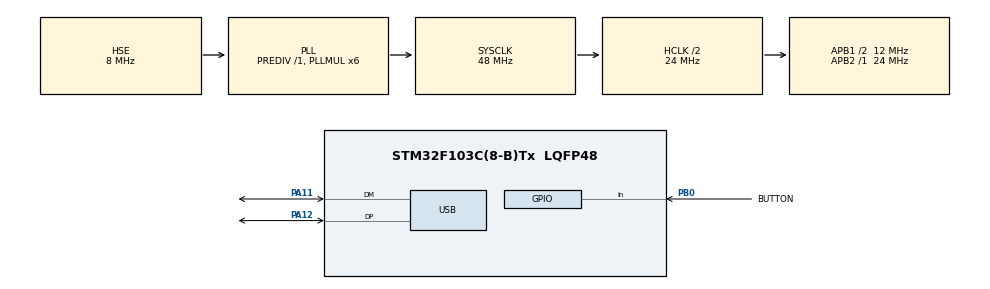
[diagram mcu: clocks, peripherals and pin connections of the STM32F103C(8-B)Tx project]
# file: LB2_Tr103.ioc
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Mcu.Family=STM32F1
Mcu.Name=STM32F103C(8-B)Tx
Mcu.Package=LQFP48
NVIC.PriorityGroup=NVIC_PRIORITYGROUP_4
NVIC.TIM2_IRQn=true\:0\:0\:false\:false\:true\:true\:true\:true
NVIC.TIM4_IRQn=true\:0\:0\:false\:false\:true\:true\:true\:true
NVIC.USB_LP_CAN1_RX0_IRQn=true\:0\:0\:false\:false\:true\:false\:true\:true
PA11.Mode=Device
PA11.Signal=USB_DM
PA12.Mode=Device
PA12.Signal=USB_DP
PA13.Mode=Serial_Wire
PA13.Signal=SYS_JTMS-SWDIO
PA14.Mode=Serial_Wire
PA14.Signal=SYS_JTCK-SWCLK
PB0.GPIO_Label=BUTTON
PB0.Signal=GPIO_Input
PD0-OSC_IN.Mode=HSE-External-Oscillator
PD0-OSC_IN.Signal=RCC_OSC_IN
PD1-OSC_OUT.Mode=HSE-External-Oscillator
PD1-OSC_OUT.Signal=RCC_OSC_OUT
ProjectManager.HeapSize=0x200
ProjectManager.StackSize=0x400
ProjectManager.TargetToolchain=STM32CubeIDE
RCC.AHBCLKDivider=RCC_SYSCLK_DIV2
RCC.AHBFreq_Value=24000000
RCC.APB1CLKDivider=RCC_HCLK_DIV2
RCC.APB1Freq_Value=12000000
RCC.APB1TimFreq_Value=24000000
RCC.APB2Freq_Value=24000000
RCC.APB2TimFreq_Value=24000000
RCC.HCLKFreq_Value=24000000
RCC.PLLMUL=RCC_PLL_MUL6
RCC.SYSCLKFreq_VALUE=48000000
RCC.SYSCLKSource=RCC_SYSCLKSOURCE_PLLCLK
RCC.USBFreq_Value=48000000
TIM2.Channel-PWM\ Generation1\ No\ Output=TIM_CHANNEL_1
TIM2.Period=7500
TIM2.Prescaler=32
TIM4.Channel-PWM\ Generation1\ No\ Output=TIM_CHANNEL_1
TIM4.Period=7500
TIM4.Prescaler=32
USB_DEVICE.APP_RX_DATA_SIZE=1024
USB_DEVICE.APP_TX_DATA_SIZE=1024
USB_DEVICE.CLASS_NAME_FS=CDC
USB_DEVICE.VirtualMode=Cdc
USB_DEVICE.VirtualModeFS=Cdc_FS
VP_TIM2_VS_no_output1.Mode=PWM Generation1 No Output
VP_TIM4_VS_no_output1.Mode=PWM Generation1 No Output
VP_USB_DEVICE_VS_USB_DEVICE_CDC_FS.Mode=CDC_FS
board=custom

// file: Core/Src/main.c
/* USER CODE BEGIN Header */
/**
  ******************************************************************************
  * @file           : main.c
  * @brief          : Main program body
  ******************************************************************************
  * @attention
  *
  * Copyright (c) 2023 STMicroelectronics.
  * All rights reserved.
  *
  * This software is licensed under terms that can be found in the LICENSE file
  * in the root directory of this software component.
  * If no LICENSE file comes with this software, it is provided AS-IS.
  *
  ******************************************************************************
  */
/* USER CODE END Header */
#include "main.h"
#include "tim.h"
#include "usb_device.h"
#include "gpio.h"

/* USER CODE BEGIN Includes */
#include "usbd_cdc_if.h"
#include "math.h"

/* USER CODE END Includes */

/* USER CODE BEGIN PV */
uint8_t lenn;
int16_t k = 1;
int8_t status = 0;
int8_t r = 10;
int8_t poz = 0;
float T2 = 0.196;
float T1 = 0.077;
float t = 0;
float tp = 0;
float f1,f2,f3,f4,f5, F = 0, Fv = 0;
uint8_t Fit = 0, sizeL;
int8_t state = 0;
char str[2];

/* USER CODE END PV */

void SystemClock_Config(void);

int main(void)
{

  /* MCU Configuration--------------------------------------------------------*/

  /* Reset of all peripherals, Initializes the Flash interface and the Systick. */
  HAL_Init();

  /* Configure the system clock */
  SystemClock_Config();

  /* Initialize all configured peripherals */
  MX_GPIO_Init();
  MX_USB_DEVICE_Init();
  MX_TIM2_Init();
  MX_TIM4_Init();
  /* USER CODE BEGIN 2 */
  HAL_TIM_Base_Start_IT(&htim2);
  HAL_TIM_Base_Start_IT(&htim4);
  /* USER CODE END 2 */

  /* Infinite loop */
  /* USER CODE BEGIN WHILE */
  while (1)
  {
	  status = HAL_GPIO_ReadPin(BUTTON_GPIO_Port, BUTTON_Pin);
	  if (status == 1 && poz != 1) {
		  r = rand() % 4;
		  tp = 0;
		  poz = 1;
	  }
	  else if (status == 0 && poz == 1) {
		  poz = 10;
	  }

	  if (r == 0) {
	  	Fv = 0.1 * (1.0206 * exp(-0.2 * tp) * sin(0.9798 * tp));
	  }
	  else if (r == 1) {
	  	Fv = 0.3 * (1.0206 * exp(-0.2 * tp) * sin(0.9798 * tp));
	  }
	  else if (r == 2) {
	  	Fv = 0.55 * (1.0206 * exp(-0.2 * tp) * sin(0.9798 * tp));
	  }
	  else if (r == 3) {
	  	Fv = 0.7 * (1.0206 * exp(-0.2 * tp) * sin(0.9798 * tp));
	  }

	  f1 = sqrt((4*pow(T2,2) - pow(T1,2))/(4*pow(T2,4)));
	  f2 = -T1 * k * exp(-T1*t/(2*pow(T2,2)))*sin(t * f1);
	  f3 = 2 * pow(T2,2) * k * f1;
	  f4 = - 2 * pow(T2,2) * k * f1 * exp(-T1*t/(2*pow(T2,2))) * cos(t * f1);
	  f5 = 2 * pow(T2,2) * f1;
	  F = (f2 + f3 + f4) / f5 + Fv;
	  Fit = (uint8_t) round(F * 10);

	  sizeL = sprintf(str, "%u\n", Fit);

	  CDC_Transmit_FS((uint8_t*) str, sizeL);

	  HAL_Delay(10);

    /* USER CODE END WHILE */

  }
}

void SystemClock_Config(void)
{
  RCC_OscInitTypeDef RCC_OscInitStruct = {0};
  RCC_ClkInitTypeDef RCC_ClkInitStruct = {0};
  RCC_PeriphCLKInitTypeDef PeriphClkInit = {0};

  /** Initializes the RCC Oscillators according to the specified parameters
  * in the RCC_OscInitTypeDef structure.
  */
  RCC_OscInitStruct.OscillatorType = RCC_OSCILLATORTYPE_HSE;
  RCC_OscInitStruct.HSEState = RCC_HSE_ON;
  RCC_OscInitStruct.HSEPredivValue = RCC_HSE_PREDIV_DIV1;
  RCC_OscInitStruct.HSIState = RCC_HSI_ON;
  RCC_OscInitStruct.PLL.PLLState = RCC_PLL_ON;
  RCC_OscInitStruct.PLL.PLLSource = RCC_PLLSOURCE_HSE;
  RCC_OscInitStruct.PLL.PLLMUL = RCC_PLL_MUL6;
  if (HAL_RCC_OscConfig(&RCC_OscInitStruct) != HAL_OK)
  {
    Error_Handler();
  }

  /** Initializes the CPU, AHB and APB buses clocks
  */
  RCC_ClkInitStruct.ClockType = RCC_CLOCKTYPE_HCLK|RCC_CLOCKTYPE_SYSCLK
                              |RCC_CLOCKTYPE_PCLK1|RCC_CLOCKTYPE_PCLK2;
  RCC_ClkInitStruct.SYSCLKSource = RCC_SYSCLKSOURCE_PLLCLK;
  RCC_ClkInitStruct.AHBCLKDivider = RCC_SYSCLK_DIV2;
  RCC_ClkInitStruct.APB1CLKDivider = RCC_HCLK_DIV2;
  RCC_ClkInitStruct.APB2CLKDivider = RCC_HCLK_DIV1;

  if (HAL_RCC_ClockConfig(&RCC_ClkInitStruct, FLASH_LATENCY_1) != HAL_OK)
  {
    Error_Handler();
  }
  PeriphClkInit.PeriphClockSelection = RCC_PERIPHCLK_USB;
  PeriphClkInit.UsbClockSelection = RCC_USBCLKSOURCE_PLL;
  if (HAL_RCCEx_PeriphCLKConfig(&PeriphClkInit) != HAL_OK)
  {
    Error_Handler();
  }
}

void Error_Handler(void)
{
  __disable_irq();
  while (1)
  {
  }
}
